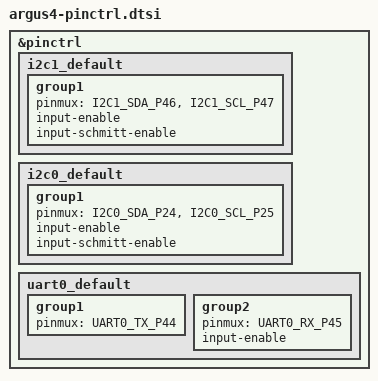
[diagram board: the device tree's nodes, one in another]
/*
 * Pin assignments for the Argus 4 mainboard.
 *
 * Authoritative source: the CircuitPython board definition at
 * FSW-mainboard/firmware/Mainboard v4/pins.c. Keep the GPIO numbers in the
 * macro names below matching that file.
 *
 * On RP2350 a pin's peripheral function is fixed by its number, so these are
 * not free choices: GPIO n can be I2Cx SDA only when n mod 4 == 0 (x=0) or
 * n mod 4 == 2 (x=1), and SCL on the pin after it. GPIO46/47 therefore give
 * I2C1, and GPIO24/25 give I2C0.
 *
 * SPDX-License-Identifier: Apache-2.0
 */

#include <zephyr/dt-bindings/pinctrl/rpi-pico-rp2350b-pinctrl.h>

&pinctrl {
	/* Peripheral I2C bus: MAX17205 fuel gauge (0x36 and shadow RAM 0x0B),
	 * on SDA1/SCL1.
	 */
	i2c1_default: i2c1_default {
		group1 {
			pinmux = <I2C1_SDA_P46>, <I2C1_SCL_P47>;
			input-enable;
			input-schmitt-enable;
		};
	};

	/* Secondary I2C bus, SDA0/SCL0. Not used by flight software yet;
	 * defined so the bus can be brought up without touching pinctrl.
	 */
	i2c0_default: i2c0_default {
		group1 {
			pinmux = <I2C0_SDA_P24>, <I2C0_SCL_P25>;
			input-enable;
			input-schmitt-enable;
		};
	};

	/* Hardware UART on TX0/RX0. The console runs over USB CDC instead, so
	 * this is available for a peripheral.
	 */
	uart0_default: uart0_default {
		group1 {
			pinmux = <UART0_TX_P44>;
		};

		group2 {
			pinmux = <UART0_RX_P45>;
			input-enable;
		};
	};
};
